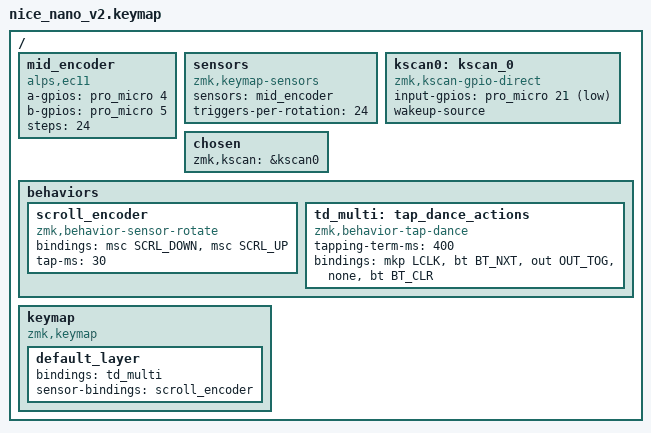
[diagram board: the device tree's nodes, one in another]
#include <behaviors.dtsi>
#include <dt-bindings/zmk/keys.h>
#include <dt-bindings/zmk/bt.h>
#include <dt-bindings/zmk/outputs.h>
/* ⚠️ 必须引入鼠标头文件，否则 &msc 会报错 */
#define ZMK_POINTING_DEFAULT_MOVE_VAL 1500  // default: 600
#define ZMK_POINTING_DEFAULT_SCRL_VAL 250    // default: 10
#include <dt-bindings/zmk/pointing.h>

/ {
    /* 硬件定义 (保持你的 Nice!Nano/Supermini 引脚设置) */
    mid_encoder: mid_encoder { 
        compatible = "alps,ec11";
        status = "okay";
        a-gpios = <&pro_micro 4 (GPIO_ACTIVE_HIGH | GPIO_PULL_UP)>;
        b-gpios = <&pro_micro 5 (GPIO_ACTIVE_HIGH | GPIO_PULL_UP)>;
        /* 如果转动不灵敏，尝试改为 48 或 80 */
        steps = <24>; 
    };

    sensors {
        compatible = "zmk,keymap-sensors";
        sensors = <&mid_encoder>;
        triggers-per-rotation = <24>;
    };

    kscan0: kscan_0 {
        compatible = "zmk,kscan-gpio-direct";
        input-gpios = <&pro_micro 21 (GPIO_ACTIVE_LOW | GPIO_PULL_UP)>;
        wakeup-source;
    };

    chosen {
        zmk,kscan = &kscan0;
    };

    behaviors {
        /* * 🖱️ 鼠标滚轮逻辑 (Scroll Encoder)
         * ------------------------------------------------
         * &msc SCRL_DOWN : 模拟鼠标滚轮向后滚 (通常是网页向下翻)
         * &msc SCRL_UP   : 模拟鼠标滚轮向前滚 (通常是网页向上翻)
         */
        scroll_encoder: scroll_encoder {
            compatible = "zmk,behavior-sensor-rotate";
            #sensor-binding-cells = <0>;
            /* * 如果方向反了 (顺时针变成了上滚)，
             * 请将下面两个指令互换位置： <&msc SCRL_UP>, <&msc SCRL_DOWN>
             */
            bindings = <&msc SCRL_DOWN>, <&msc SCRL_UP>;
            tap-ms = <30>; 
        };

        /* 按钮逻辑 (保留之前的多功能设置) */
        td_multi: tap_dance_actions {
            compatible = "zmk,behavior-tap-dance";
            #binding-cells = <0>;
            tapping-term-ms = <400>;
            bindings = <&mkp LCLK>, <&bt BT_NXT>, <&out OUT_TOG>, <&none>, <&bt BT_CLR>;
        };
    };

    keymap {
        compatible = "zmk,keymap";
        default_layer {
            bindings = < &td_multi >;
            /* 这里绑定刚才定义的滚轮行为 */
            sensor-bindings = <&scroll_encoder>;
        };
    };
};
